# CW32F030 register map
Vendor: Wuhan Xinyuan Semiconductor Co.Ltd; Series: ARMCM0P; File version: 1.2
CPU: CM0+ r0p1, little endian, no MPU, no FPU, 3 interrupt priority bits
Registers are 32-bit, read-write, no defined reset value unless marked. A register's access mark holds for its fields unless they carry their own. Offsets are from the block's base; [hi:lo] are bit positions; {n}, {i} and the like mark numbered series.

## AWT
Base 0x40014C00
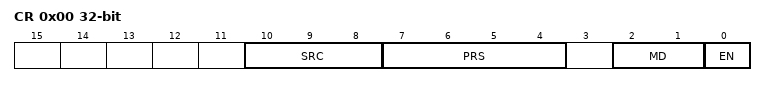
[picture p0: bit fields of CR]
0x00 CR — Control register
  [10:8] SRC, [7:4] PRS, [2:1] MD, [0] EN
0x04 ARR — Auto reload register
  [15:0] ARR
0x08 CNT ro — counter
  [15:0] CNT
0x10 IER — Interrupt enable register
  [3] UD
0x14 ISR ro — Interrupt status register
  [3] UD
0x1C ICR — Interrupt flag clear register
  [3] UD

## BTIM1 — Base Timer 1
Base 0x40014800
Same registers: BTIM2 0x40014900, BTIM3 0x40014A00
0x00 ARR — Auto Reload Register
  [15:0] ARR
0x04 CNT — Counter Register
  [15:0] CNT
0x0C ACR — Advanced Control register
  [6:4] ETRFLT
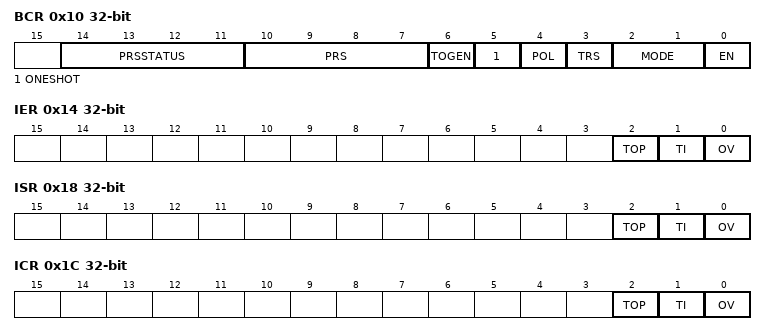
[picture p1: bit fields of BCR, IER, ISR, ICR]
0x10 BCR — Base Control register
  [14:11] PRSSTATUS ro, [10:7] PRS, [6] TOGEN, [5] ONESHOT, [4] POL, [3] TRS, [2:1] MODE, [0] EN
0x14 IER — Interrupt enable register
  [2] TOP, [1] TI, [0] OV
0x18 ISR ro — Interrupt status register
  [2] TOP, [1] TI, [0] OV
0x1C ICR — Interrupt flag clear register
  [2] TOP, [1] TI, [0] OV
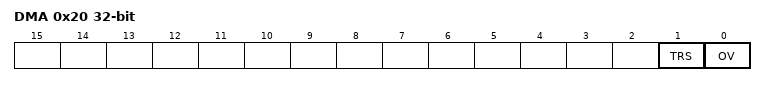
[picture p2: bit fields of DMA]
0x20 DMA — DMA control register
  [1] TRS, [0] OV

## CRC
Base 0x40023000
0x00 CR — Control register
  [3:0] MODE
0x08 DR32 — Data register
0x08 DR16 16-bit (alternate view of DR32) — Data register
0x08 DR8 8-bit (alternate view of DR32) — Data register
0x0C RESULT32 ro — Result register
0x0C RESULT16 16-bit ro (alternate view of RESULT32) — Result register

## DMA
Base 0x40020000
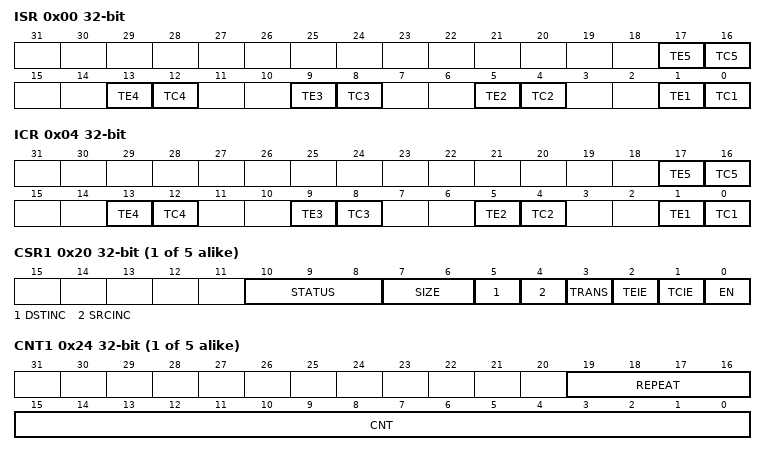
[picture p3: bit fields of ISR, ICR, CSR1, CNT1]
0x00 ISR ro — Interrupt status register
  [4n-3] TE{n} (n=1..5), [4n-4] TC{n} (n=1..5)
0x04 ICR — Interrupt flag clear register
  [4n-3] TE{n} (n=1..5), [4n-4] TC{n} (n=1..5)
{0x0+0x20*i} CSR{i} (i=1..5) — Channel{i} control and status register
  [10:8] STATUS ro, [7:6] SIZE, [5] DSTINC, [4] SRCINC, [3] TRANS, [2] TEIE, [1] TCIE, [0] EN
{0x4+0x20*i} CNT{i} (i=1..5) — Channel{i} counter register
  [19:16] REPEAT, [15:0] CNT
{0x8+0x20*i} SRCADDR{i} (i=1..5) — Channel{i} source address register
  [31:0] SRCADDR
{0xC+0x20*i} DSTADDR{i} (i=1..5) — Channel{i} destination address register
  [31:0] DSTADDR
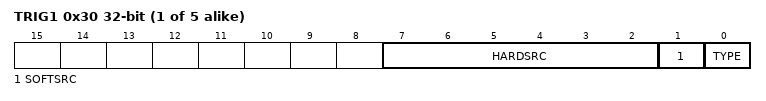
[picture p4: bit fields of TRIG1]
{0x10+0x20*i} TRIG{i} (i=1..5) — Channel{i} trigger register
  [7:2] HARDSRC, [1] SOFTSRC, [0] TYPE

## DMACHANNEL1
Base 0x40020020; alternate view of DMA
Same registers: DMACHANNEL2 0x40020040, DMACHANNEL3 0x40020060, DMACHANNEL4 0x40020080, DMACHANNEL5 0x400200A0
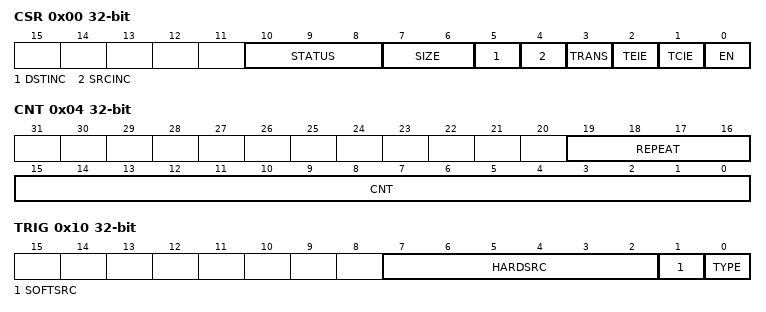
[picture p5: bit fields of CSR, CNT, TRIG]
0x00 CSR — Channel.y control and status register
  [10:8] STATUS ro, [7:6] SIZE, [5] DSTINC, [4] SRCINC, [3] TRANS, [2] TEIE, [1] TCIE, [0] EN
0x04 CNT — Channel.y counter register
  [19:16] REPEAT, [15:0] CNT
0x08 SRCADDR — Channel.y source address register
0x0C DSTADDR — Channel.y destination address register
0x10 TRIG — Channel.y trigger register
  [7:2] HARDSRC, [1] SOFTSRC, [0] TYPE

## FLASH
Base 0x40022000
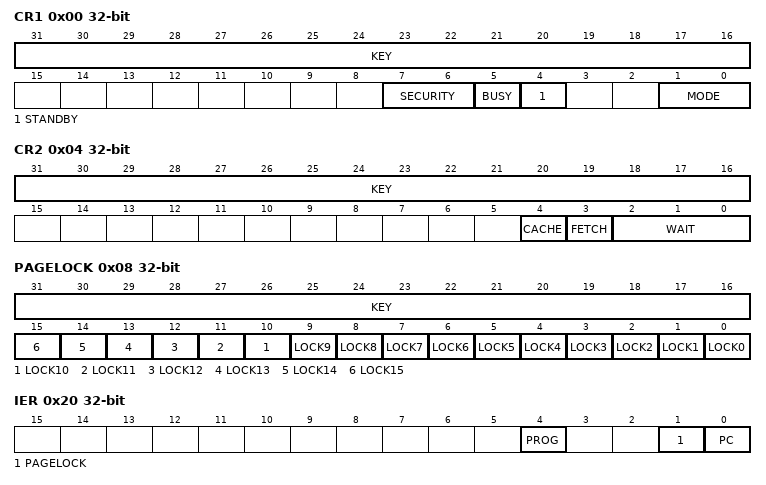
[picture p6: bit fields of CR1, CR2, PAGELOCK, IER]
0x00 CR1 — Control register1
  [31:16] KEY wo, [7:6] SECURITY ro, [5] BUSY ro, [4] STANDBY, [1:0] MODE
0x04 CR2 — Control register2
  [31:16] KEY wo, [4] CACHE, [3] FETCH, [2:0] WAIT
0x08 PAGELOCK — Page Write Erase Lock
  [31:16] KEY wo
  [n] LOCK{n} (n=0..15) — Page{8n} - {8n+7}
0x20 IER — Interrupt enable register
  [4] PROG, [1] PAGELOCK, [0] PC
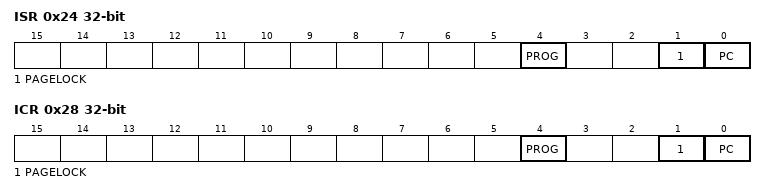
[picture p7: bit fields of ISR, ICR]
0x24 ISR ro — Interrupt status register
  [4] PROG, [1] PAGELOCK, [0] PC
0x28 ICR — Interrupt flag clear register
  [4] PROG, [1] PAGELOCK, [0] PC

## GPIOA
Base 0x48000000
Same registers: GPIOB 0x48000400
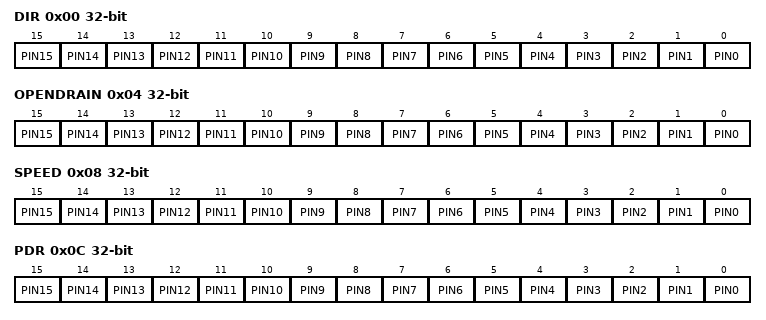
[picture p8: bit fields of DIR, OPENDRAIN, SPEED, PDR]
0x00 DIR
  [n] PIN{n} (n=0..15)
0x04 OPENDRAIN
  [n] PIN{n} (n=0..15)
0x08 SPEED
  [n] PIN{n} (n=0..15)
0x0C PDR
  [n] PIN{n} (n=0..15)
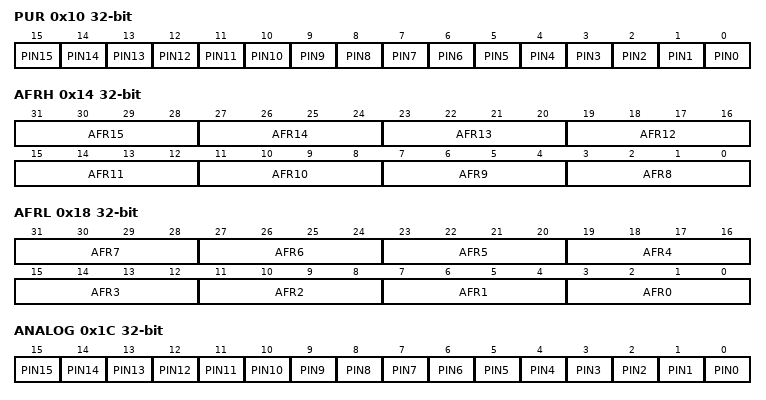
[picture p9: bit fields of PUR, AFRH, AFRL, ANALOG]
0x10 PUR
  [n] PIN{n} (n=0..15)
0x14 AFRH
  [4n-29:4n-32] AFR{n} (n=8..15)
0x18 AFRL
  [4n+3:4n] AFR{n} (n=0..7)
0x1C ANALOG
  [n] PIN{n} (n=0..15)
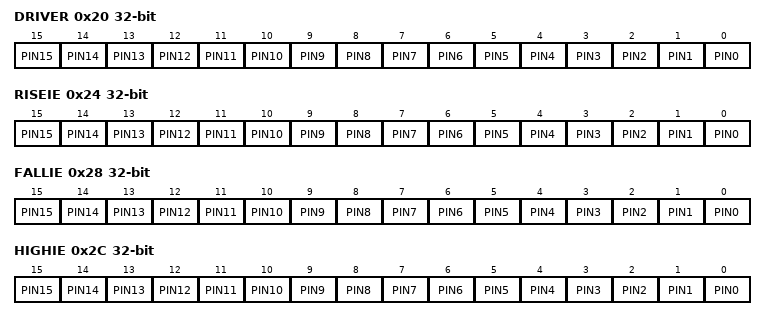
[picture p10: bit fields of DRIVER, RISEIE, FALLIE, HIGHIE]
0x20 DRIVER
  [n] PIN{n} (n=0..15)
0x24 RISEIE — Interrupt enable register
  [n] PIN{n} (n=0..15)
0x28 FALLIE — Interrupt enable register
  [n] PIN{n} (n=0..15)
0x2C HIGHIE — Interrupt enable register
  [n] PIN{n} (n=0..15)
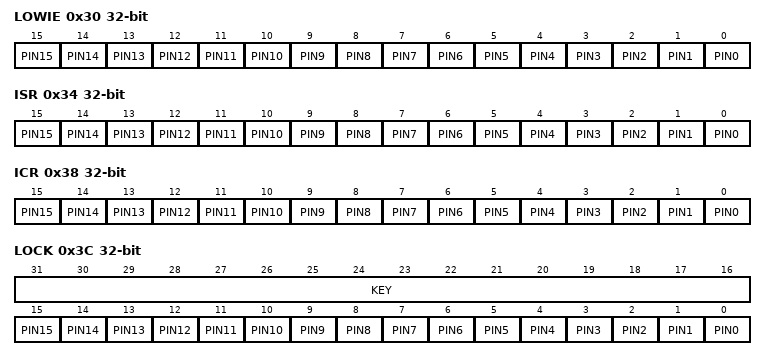
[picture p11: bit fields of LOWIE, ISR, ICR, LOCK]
0x30 LOWIE — Interrupt enable register
  [n] PIN{n} (n=0..15)
0x34 ISR — Interrupt status register
  [n] PIN{n} (n=0..15)
0x38 ICR — Interrupt flag clear register
  [n] PIN{n} (n=0..15)
0x3C LOCK
  [31:16] KEY wo — KEY = 0x5A5A
  [n] PIN{n} (n=0..15)
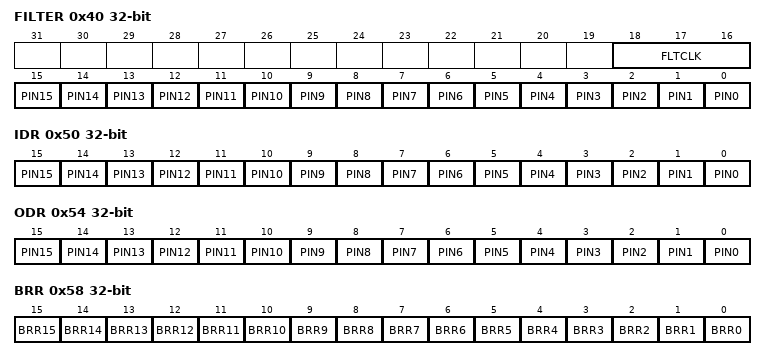
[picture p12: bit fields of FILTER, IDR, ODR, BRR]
0x40 FILTER
  [18:16] FLTCLK, [n] PIN{n} (n=0..15)
0x50 IDR ro
  [n] PIN{n} (n=0..15)
0x54 ODR
  [n] PIN{n} (n=0..15)
0x54 ODRLOWBYTE 8-bit (alternate view of ODR)
  [7:0] LOWBYTE
0x55 ODRHIGHBYTE 8-bit (alternate view of ODR)
  [7:0] HIGHBYTE
0x58 BRR
  [n] BRR{n} (n=0..15)
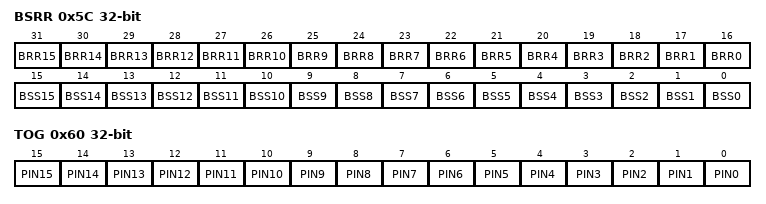
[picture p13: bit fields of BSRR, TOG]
0x5C BSRR
  [n+16] BRR{n} (n=0..15), [n] BSS{n} (n=0..15)
0x60 TOG
  [n] PIN{n} (n=0..15)
